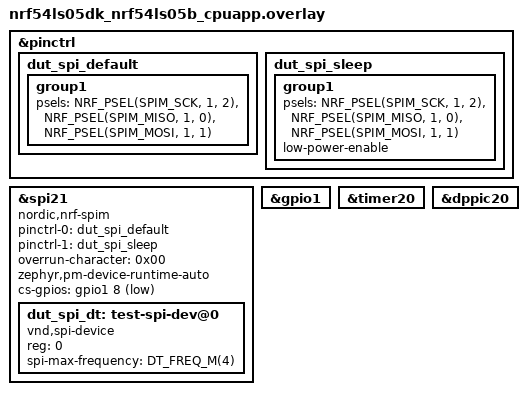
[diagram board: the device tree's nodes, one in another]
/*
 * Copyright (c) 2025 Nordic Semiconductor ASA
 *
 * SPDX-License-Identifier: LicenseRef-Nordic-5-Clause
 */

/* Required loopbacks:
 * P1.00 <-> P1.01
 */

&pinctrl {
	dut_spi_default: dut_spi_default {
		group1 {
			psels = <NRF_PSEL(SPIM_SCK, 1, 2)>,
				<NRF_PSEL(SPIM_MISO, 1, 0)>,
				<NRF_PSEL(SPIM_MOSI, 1, 1)>;
		};
	};

	dut_spi_sleep: dut_spi_sleep {
		group1 {
			psels = <NRF_PSEL(SPIM_SCK, 1, 2)>,
				<NRF_PSEL(SPIM_MISO, 1, 0)>,
				<NRF_PSEL(SPIM_MOSI, 1, 1)>;
			low-power-enable;
		};
	};
};

dut_spi: &spi21 {
	compatible = "nordic,nrf-spim";
	status = "okay";
	pinctrl-0 = <&dut_spi_default>;
	pinctrl-1 = <&dut_spi_sleep>;
	pinctrl-names = "default", "sleep";
	overrun-character = <0x00>;
	zephyr,pm-device-runtime-auto;
	cs-gpios = <&gpio1 8 GPIO_ACTIVE_LOW>;

	dut_spi_dt: test-spi-dev@0 {
		compatible = "vnd,spi-device";
		reg = <0>;
		spi-max-frequency = <DT_FREQ_M(4)>;
	};
};

&gpio1 {
	status = "okay";
};

tst_timer: &timer20 {
	status = "okay";
};

&dppic20 {
	status = "okay";
};
